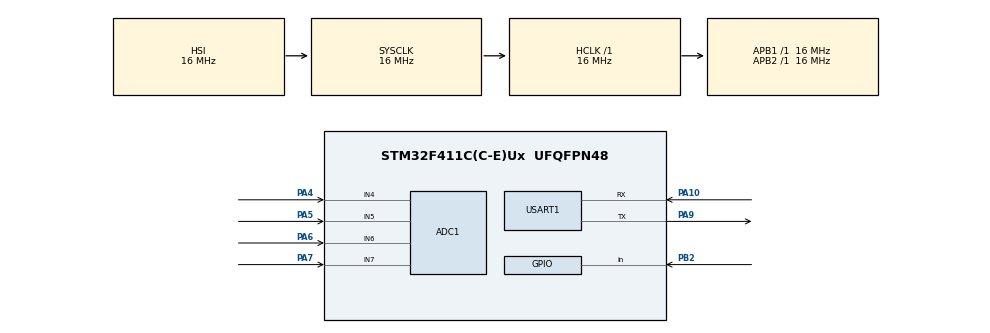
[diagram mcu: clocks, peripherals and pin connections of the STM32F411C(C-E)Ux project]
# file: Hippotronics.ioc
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ADC1.Channel-0\#ChannelRegularConversion=ADC_CHANNEL_7
ADC1.NbrOfConversionFlag=1
ADC1.Rank-0\#ChannelRegularConversion=1
ADC1.SamplingTime-0\#ChannelRegularConversion=ADC_SAMPLETIME_3CYCLES
ADC1.master=1
Mcu.Family=STM32F4
Mcu.Name=STM32F411C(C-E)Ux
Mcu.Package=UFQFPN48
NVIC.PriorityGroup=NVIC_PRIORITYGROUP_4
PA0-WKUP.Signal=S_TIM5_CH1
PA1.Signal=S_TIM5_CH2
PA10.Mode=Asynchronous
PA10.Signal=USART1_RX
PA11.Signal=S_TIM1_CH4
PA13.Signal=SYS_JTMS-SWDIO
PA14.Signal=SYS_JTCK-SWCLK
PA15.Signal=S_TIM2_CH1_ETR
PA2.Signal=S_TIM5_CH3
PA3.Signal=S_TIM5_CH4
PA4.Signal=SharedAnalog_PA4
PA5.Signal=SharedAnalog_PA5
PA6.Signal=SharedAnalog_PA6
PA7.Signal=SharedAnalog_PA7
PA8.Signal=S_TIM1_CH1
PA9.Mode=Asynchronous
PA9.Signal=USART1_TX
PB0.Signal=TIM1_CH2N
PB1.Signal=TIM1_CH3N
PB10.Signal=I2C2_SCL
PB13.Signal=SPI2_SCK
PB14.Signal=SPI2_MISO
PB15.Signal=SPI2_MOSI
PB2.Signal=GPIO_Input
PB3.Signal=S_TIM2_CH2
PB4.Signal=S_TIM3_CH1
PB5.Signal=S_TIM3_CH2
PB6.Signal=S_TIM4_CH1
PB7.Signal=S_TIM4_CH2
PB8.Signal=S_TIM10_CH1
PB9.Signal=I2C2_SDA
ProjectManager.HeapSize=0x200
ProjectManager.StackSize=0x400
ProjectManager.TargetToolchain=STM32CubeIDE
RCC.AHBFreq_Value=16000000
RCC.APB1Freq_Value=16000000
RCC.APB2Freq_Value=16000000
RCC.CortexFreq_Value=16000000
RCC.HSE_VALUE=25000000
RCC.HSI_VALUE=16000000
RCC.LSE_VALUE=32768
RCC.SYSCLKFreq_VALUE=16000000
RCC.VCOOutputFreq_Value=192000000
SH.S_TIM10_CH1.0=TIM10_CH1
SH.S_TIM1_CH1.0=TIM1_CH1
SH.S_TIM1_CH4.0=TIM1_CH4
SH.S_TIM2_CH1_ETR.0=TIM2_CH1
SH.S_TIM2_CH2.0=TIM2_CH2
SH.S_TIM3_CH1.0=TIM3_CH1
SH.S_TIM3_CH2.0=TIM3_CH2
SH.S_TIM4_CH1.0=TIM4_CH1
SH.S_TIM4_CH2.0=TIM4_CH2
SH.S_TIM5_CH1.0=TIM5_CH1
SH.S_TIM5_CH2.0=TIM5_CH2
SH.S_TIM5_CH3.0=TIM5_CH3
SH.S_TIM5_CH4.0=TIM5_CH4
SH.SharedAnalog_PA4.0=GPIO_Analog
SH.SharedAnalog_PA4.1=ADC1_IN4,IN4
SH.SharedAnalog_PA5.0=GPIO_Analog
SH.SharedAnalog_PA5.1=ADC1_IN5,IN5
SH.SharedAnalog_PA6.0=GPIO_Analog
SH.SharedAnalog_PA6.1=ADC1_IN6,IN6
SH.SharedAnalog_PA7.0=GPIO_Analog
SH.SharedAnalog_PA7.1=ADC1_IN7,IN7
USART1.VirtualMode=VM_ASYNC
board=custom

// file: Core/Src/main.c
/* USER CODE BEGIN Header */
/**
  ******************************************************************************
  * @file           : main.c
  * @brief          : Main program body
  ******************************************************************************
  * @attention
  *
  * Copyright (c) 2023 STMicroelectronics.
  * All rights reserved.
  *
  * This software is licensed under terms that can be found in the LICENSE file
  * in the root directory of this software component.
  * If no LICENSE file comes with this software, it is provided AS-IS.
  *
  ******************************************************************************
  */
/* USER CODE END Header */
#include "main.h"

ADC_HandleTypeDef hadc1;

UART_HandleTypeDef huart1;

void SystemClock_Config(void);
static void MX_GPIO_Init(void);
static void MX_ADC1_Init(void);
static void MX_USART1_UART_Init(void);

int main(void)
{

  /* MCU Configuration--------------------------------------------------------*/

  /* Reset of all peripherals, Initializes the Flash interface and the Systick. */
  HAL_Init();

  /* Configure the system clock */
  SystemClock_Config();

  /* Initialize all configured peripherals */
  MX_GPIO_Init();
  MX_ADC1_Init();
  MX_USART1_UART_Init();
  /* USER CODE BEGIN 2 */
  char msg_buff[100] = {0};

  int32_t len = sprintf(msg_buff, "HELLO WORLD! \n\r");

  HAL_UART_Transmit(&huart1, (uint8_t*) msg_buff, len, 1000);

  /* USER CODE END 2 */

  /* Infinite loop */
  while (1)
  {
	  HAL_UART_Transmit(&huart1, (uint8_t*) msg_buff, len, 1000);
  }
}

void SystemClock_Config(void)
{
  RCC_OscInitTypeDef RCC_OscInitStruct = {0};
  RCC_ClkInitTypeDef RCC_ClkInitStruct = {0};

  /** Configure the main internal regulator output voltage
  */
  __HAL_RCC_PWR_CLK_ENABLE();
  __HAL_PWR_VOLTAGESCALING_CONFIG(PWR_REGULATOR_VOLTAGE_SCALE1);

  /** Initializes the RCC Oscillators according to the specified parameters
  * in the RCC_OscInitTypeDef structure.
  */
  RCC_OscInitStruct.OscillatorType = RCC_OSCILLATORTYPE_HSI;
  RCC_OscInitStruct.HSIState = RCC_HSI_ON;
  RCC_OscInitStruct.HSICalibrationValue = RCC_HSICALIBRATION_DEFAULT;
  RCC_OscInitStruct.PLL.PLLState = RCC_PLL_NONE;
  if (HAL_RCC_OscConfig(&RCC_OscInitStruct) != HAL_OK)
  {
    Error_Handler();
  }

  /** Initializes the CPU, AHB and APB buses clocks
  */
  RCC_ClkInitStruct.ClockType = RCC_CLOCKTYPE_HCLK|RCC_CLOCKTYPE_SYSCLK
                              |RCC_CLOCKTYPE_PCLK1|RCC_CLOCKTYPE_PCLK2;
  RCC_ClkInitStruct.SYSCLKSource = RCC_SYSCLKSOURCE_HSI;
  RCC_ClkInitStruct.AHBCLKDivider = RCC_SYSCLK_DIV1;
  RCC_ClkInitStruct.APB1CLKDivider = RCC_HCLK_DIV1;
  RCC_ClkInitStruct.APB2CLKDivider = RCC_HCLK_DIV1;

  if (HAL_RCC_ClockConfig(&RCC_ClkInitStruct, FLASH_LATENCY_0) != HAL_OK)
  {
    Error_Handler();
  }
}

static void MX_ADC1_Init(void)
{

  ADC_ChannelConfTypeDef sConfig = {0};

  /** Configure the global features of the ADC (Clock, Resolution, Data Alignment and number of conversion)
  */
  hadc1.Instance = ADC1;
  hadc1.Init.ClockPrescaler = ADC_CLOCK_SYNC_PCLK_DIV2;
  hadc1.Init.Resolution = ADC_RESOLUTION_12B;
  hadc1.Init.ScanConvMode = DISABLE;
  hadc1.Init.ContinuousConvMode = DISABLE;
  hadc1.Init.DiscontinuousConvMode = DISABLE;
  hadc1.Init.ExternalTrigConvEdge = ADC_EXTERNALTRIGCONVEDGE_NONE;
  hadc1.Init.ExternalTrigConv = ADC_SOFTWARE_START;
  hadc1.Init.DataAlign = ADC_DATAALIGN_RIGHT;
  hadc1.Init.NbrOfConversion = 1;
  hadc1.Init.DMAContinuousRequests = DISABLE;
  hadc1.Init.EOCSelection = ADC_EOC_SINGLE_CONV;
  if (HAL_ADC_Init(&hadc1) != HAL_OK)
  {
    Error_Handler();
  }

  /** Configure for the selected ADC regular channel its corresponding rank in the sequencer and its sample time.
  */
  sConfig.Channel = ADC_CHANNEL_7;
  sConfig.Rank = 1;
  sConfig.SamplingTime = ADC_SAMPLETIME_3CYCLES;
  if (HAL_ADC_ConfigChannel(&hadc1, &sConfig) != HAL_OK)
  {
    Error_Handler();
  }

}

static void MX_USART1_UART_Init(void)
{

  huart1.Instance = USART1;
  huart1.Init.BaudRate = 115200;
  huart1.Init.WordLength = UART_WORDLENGTH_8B;
  huart1.Init.StopBits = UART_STOPBITS_1;
  huart1.Init.Parity = UART_PARITY_NONE;
  huart1.Init.Mode = UART_MODE_TX_RX;
  huart1.Init.HwFlowCtl = UART_HWCONTROL_NONE;
  huart1.Init.OverSampling = UART_OVERSAMPLING_16;
  if (HAL_UART_Init(&huart1) != HAL_OK)
  {
    Error_Handler();
  }

}

static void MX_GPIO_Init(void)
{
  GPIO_InitTypeDef GPIO_InitStruct = {0};

  /* GPIO Ports Clock Enable */
  __HAL_RCC_GPIOA_CLK_ENABLE();
  __HAL_RCC_GPIOB_CLK_ENABLE();

  /*Configure GPIO pins : PA0 PA1 PA2 PA3 */
  GPIO_InitStruct.Pin = GPIO_PIN_0|GPIO_PIN_1|GPIO_PIN_2|GPIO_PIN_3;
  GPIO_InitStruct.Mode = GPIO_MODE_AF_PP;
  GPIO_InitStruct.Pull = GPIO_NOPULL;
  GPIO_InitStruct.Speed = GPIO_SPEED_FREQ_LOW;
  GPIO_InitStruct.Alternate = GPIO_AF2_TIM5;
  HAL_GPIO_Init(GPIOA, &GPIO_InitStruct);

  /*Configure GPIO pins : PB0 PB1 */
  GPIO_InitStruct.Pin = GPIO_PIN_0|GPIO_PIN_1;
  GPIO_InitStruct.Mode = GPIO_MODE_AF_PP;
  GPIO_InitStruct.Pull = GPIO_NOPULL;
  GPIO_InitStruct.Speed = GPIO_SPEED_FREQ_LOW;
  GPIO_InitStruct.Alternate = GPIO_AF1_TIM1;
  HAL_GPIO_Init(GPIOB, &GPIO_InitStruct);

  /*Configure GPIO pin : PB2 */
  GPIO_InitStruct.Pin = GPIO_PIN_2;
  GPIO_InitStruct.Mode = GPIO_MODE_INPUT;
  GPIO_InitStruct.Pull = GPIO_NOPULL;
  HAL_GPIO_Init(GPIOB, &GPIO_InitStruct);

  /*Configure GPIO pin : PB10 */
  GPIO_InitStruct.Pin = GPIO_PIN_10;
  GPIO_InitStruct.Mode = GPIO_MODE_AF_OD;
  GPIO_InitStruct.Pull = GPIO_NOPULL;
  GPIO_InitStruct.Speed = GPIO_SPEED_FREQ_VERY_HIGH;
  GPIO_InitStruct.Alternate = GPIO_AF4_I2C2;
  HAL_GPIO_Init(GPIOB, &GPIO_InitStruct);

  /*Configure GPIO pins : PB13 PB14 PB15 */
  GPIO_InitStruct.Pin = GPIO_PIN_13|GPIO_PIN_14|GPIO_PIN_15;
  GPIO_InitStruct.Mode = GPIO_MODE_AF_PP;
  GPIO_InitStruct.Pull = GPIO_NOPULL;
  GPIO_InitStruct.Speed = GPIO_SPEED_FREQ_VERY_HIGH;
  GPIO_InitStruct.Alternate = GPIO_AF5_SPI2;
  HAL_GPIO_Init(GPIOB, &GPIO_InitStruct);

  /*Configure GPIO pins : PA8 PA11 */
  GPIO_InitStruct.Pin = GPIO_PIN_8|GPIO_PIN_11;
  GPIO_InitStruct.Mode = GPIO_MODE_AF_PP;
  GPIO_InitStruct.Pull = GPIO_NOPULL;
  GPIO_InitStruct.Speed = GPIO_SPEED_FREQ_LOW;
  GPIO_InitStruct.Alternate = GPIO_AF1_TIM1;
  HAL_GPIO_Init(GPIOA, &GPIO_InitStruct);

  /*Configure GPIO pin : PA15 */
  GPIO_InitStruct.Pin = GPIO_PIN_15;
  GPIO_InitStruct.Mode = GPIO_MODE_AF_PP;
  GPIO_InitStruct.Pull = GPIO_NOPULL;
  GPIO_InitStruct.Speed = GPIO_SPEED_FREQ_LOW;
  GPIO_InitStruct.Alternate = GPIO_AF1_TIM2;
  HAL_GPIO_Init(GPIOA, &GPIO_InitStruct);

  /*Configure GPIO pin : PB3 */
  GPIO_InitStruct.Pin = GPIO_PIN_3;
  GPIO_InitStruct.Mode = GPIO_MODE_AF_PP;
  GPIO_InitStruct.Pull = GPIO_NOPULL;
  GPIO_InitStruct.Speed = GPIO_SPEED_FREQ_LOW;
  GPIO_InitStruct.Alternate = GPIO_AF1_TIM2;
  HAL_GPIO_Init(GPIOB, &GPIO_InitStruct);

  /*Configure GPIO pins : PB4 PB5 */
  GPIO_InitStruct.Pin = GPIO_PIN_4|GPIO_PIN_5;
  GPIO_InitStruct.Mode = GPIO_MODE_AF_PP;
  GPIO_InitStruct.Pull = GPIO_NOPULL;
  GPIO_InitStruct.Speed = GPIO_SPEED_FREQ_LOW;
  GPIO_InitStruct.Alternate = GPIO_AF2_TIM3;
  HAL_GPIO_Init(GPIOB, &GPIO_InitStruct);

  /*Configure GPIO pins : PB6 PB7 */
  GPIO_InitStruct.Pin = GPIO_PIN_6|GPIO_PIN_7;
  GPIO_InitStruct.Mode = GPIO_MODE_AF_PP;
  GPIO_InitStruct.Pull = GPIO_NOPULL;
  GPIO_InitStruct.Speed = GPIO_SPEED_FREQ_LOW;
  GPIO_InitStruct.Alternate = GPIO_AF2_TIM4;
  HAL_GPIO_Init(GPIOB, &GPIO_InitStruct);

  /*Configure GPIO pin : PB8 */
  GPIO_InitStruct.Pin = GPIO_PIN_8;
  GPIO_InitStruct.Mode = GPIO_MODE_AF_PP;
  GPIO_InitStruct.Pull = GPIO_NOPULL;
  GPIO_InitStruct.Speed = GPIO_SPEED_FREQ_LOW;
  GPIO_InitStruct.Alternate = GPIO_AF3_TIM10;
  HAL_GPIO_Init(GPIOB, &GPIO_InitStruct);

  /*Configure GPIO pin : PB9 */
  GPIO_InitStruct.Pin = GPIO_PIN_9;
  GPIO_InitStruct.Mode = GPIO_MODE_AF_OD;
  GPIO_InitStruct.Pull = GPIO_NOPULL;
  GPIO_InitStruct.Speed = GPIO_SPEED_FREQ_VERY_HIGH;
  GPIO_InitStruct.Alternate = GPIO_AF9_I2C2;
  HAL_GPIO_Init(GPIOB, &GPIO_InitStruct);

}

void Error_Handler(void)
{
  __disable_irq();
  while (1)
  {
  }
}
